# PIC32CX5112MTSH128S1 device description
Architecture: CORTEX-M4; Family: PIC32CXMT; Series: PIC32CXMTSH
Registers are 32-bit, read-write, no defined reset value unless marked. A register's access mark holds for its fields unless they carry their own. Offsets are from the block's base; [hi:lo] are bit positions; {n}, {i} and the like mark numbered series; 'fields as' and 'values as' point back to an identical list; <NAME> marks a mode.

## FLEXCOM (part 1 of 2) — Flexible Serial Communication
Instances: FLEXCOM{n} {0x40000000+0x4000*n} (n=0..7)
0x00 FLEX_MR — FLEXCOM Mode Register
  [1:0] OPMODE — FLEXCOM Operating Mode
    0=NO_COM (No communication); 1=USART (All UART related protocols are selected (RS232, RS485, IrDA, ISO7816, LIN,) SPI/TWI related registers are not accessible and have no impact on IOs.); 2=SPI (SPI operating mode is selected. USART/TWI related registers are not accessible and have no impact on IOs.); 3=TWI (All TWI related protocols are selected (TWI, SMBus). USART/SPI related registers are not accessible and have no impact on IOs.)
0x10 FLEX_RHR ro — FLEXCOM Receive Holding Register
  [15:0] RXDATA — Receive Data
0x20 FLEX_THR — FLEXCOM Transmit Holding Register
  [15:0] TXDATA — Transmit Data
0x100 FLEX_RPR — Receive Pointer Register
  [31:0] RXPTR
0x104 FLEX_RCR — Receive Counter Register
  [15:0] RXCTR
0x108 FLEX_TPR — Transmit Pointer Register
  [31:0] TXPTR — Transmit Counter Register
0x10C FLEX_TCR — Transmit Counter Register
  [15:0] TXCTR
0x110 FLEX_RNPR — Receive Next Pointer Register
  [31:0] RXNPTR — Receive Next Pointer
0x114 FLEX_RNCR — Receive Next Counter Register
  [15:0] RXNCTR — Receive Next Counter
0x118 FLEX_TNPR — Transmit Next Pointer Register
  [31:0] TXNPTR — Transmit Next Pointer
0x11C FLEX_TNCR — Transmit Next Counter Register
  [15:0] TXNCTR — Transmit Counter Next
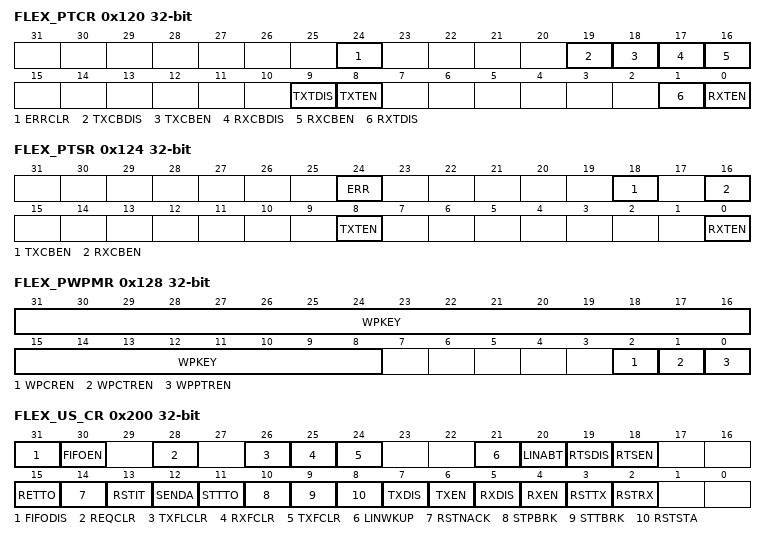
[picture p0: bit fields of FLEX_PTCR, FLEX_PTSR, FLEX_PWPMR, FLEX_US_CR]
0x120 FLEX_PTCR wo — Transfer Control Register
  [24] ERRCLR — Transfer Bus Error Clear
  [19] TXCBDIS — Transmitter Circular Buffer Disable
  [18] TXCBEN — Transmitter Circular Buffer Enable
  [17] RXCBDIS — Receiver Circular Buffer Disable
  [16] RXCBEN — Receiver Circular Buffer Enable
  [9] TXTDIS — Transmitter Transfer Disable
  [8] TXTEN — Transmitter Transfer Enable
  [1] RXTDIS — Receiver Transfer Disable
  [0] RXTEN — Receiver Transfer Enable
0x124 FLEX_PTSR ro — Transfer Status Register
  [24] ERR — Transfer Bus Error
  [18] TXCBEN — Transmitter Circular Buffer Enable
  [16] RXCBEN — Receiver Circular Buffer Enable
  [8] TXTEN — Transmitter Transfer Enable
  [0] RXTEN — Receiver Transfer Enable
0x128 FLEX_PWPMR — Write Protection Mode Register
  [31:8] WPKEY — Write Protection Key
    0x504443=PASSWD (Writing any other value in this field aborts the write operation. Always reads as 0.)
  [2] WPCREN — Write Protection Control Register Enable
  [1] WPCTREN — Write Protection Counter Registers Enable
  [0] WPPTREN — Write Protection Pointer Registers Enable
0x200 FLEX_US_CR wo — USART Control Register
  [31] FIFODIS — FIFO Disable
  [30] FIFOEN — FIFO Enable
  [28] REQCLR — Request to Clear the Comparison Trigger
  [26] TXFLCLR — Transmit FIFO Lock CLEAR
  [25] RXFCLR — Receive FIFO Clear
  [24] TXFCLR — Transmit FIFO Clear
  [21] LINWKUP — Send LIN Wakeup Signal
  [20] LINABT — Abort LIN Transmission
  [19] RTSDIS — Request to Send Disable
  [18] RTSEN — Request to Send Enable
  [15] RETTO — Start Timeout Immediately
  [14] RSTNACK — Reset Non Acknowledge
  [13] RSTIT — Reset Iterations
  [12] SENDA — Send Address
  [11] STTTO — Clear TIMEOUT Flag and Start Timeout After Next Character Received
  [10] STPBRK — Stop Break
  [9] STTBRK — Start Break
  [8] RSTSTA — Reset Status Bits
  [7] TXDIS — Transmitter Disable
  [6] TXEN — Transmitter Enable
  [5] RXDIS — Receiver Disable
  [4] RXEN — Receiver Enable
  [3] RSTTX — Reset Transmitter
  [2] RSTRX — Reset Receiver
0x204 FLEX_US_MR — USART Mode Register
  [31] ONEBIT <DEFAULT> — Start Frame Delimiter Selector
  [30] MODSYNC <DEFAULT> — Manchester Synchronization Mode
  [29] MAN <DEFAULT> — Manchester Encoder/Decoder Enable
  [28] FILTER <DEFAULT> — Receive Line Filter
  [26:24] MAX_ITERATION <DEFAULT> — Maximum Number of Automatic Iteration
  [23] INVDATA <DEFAULT> — Inverted Data
  [22] VAR_SYNC <DEFAULT> — Variable Synchronization of Command/Data Sync Start Frame Delimiter
  [21] DSNACK <DEFAULT> — Disable Successive NACK
  [20] INACK <DEFAULT> — Inhibit Non Acknowledge
  [19] OVER <DEFAULT> — Oversampling Mode
  [18] CLKO <DEFAULT> — Clock Output Select
  [17] MODE9 <DEFAULT> — 9-bit Character Length
  [16] MSBF <DEFAULT> — Bit Order
  [15:14] CHMODE <DEFAULT> — Channel Mode
    0=NORMAL (Normal mode); 1=AUTOMATIC (Automatic Echo. Receiver input is connected to the TXD pin.); 2=LOCAL_LOOPBACK (Local Loopback. Transmitter output is connected to the Receiver Input.); 3=REMOTE_LOOPBACK (Remote Loopback. RXD pin is internally connected to the TXD pin.)
  [13:12] NBSTOP <DEFAULT> — Number of Stop Bits
    0=1_BIT (1 stop bit); 1=1_5_BIT (1.5 stop bit (SYNC = 0) or reserved (SYNC = 1)); 2=2_BIT (2 stop bits)
  [11:9] PAR <DEFAULT> — Parity Type
    0=EVEN (Even parity); 1=ODD (Odd parity); 2=SPACE (Parity forced to 0 (Space)); 3=MARK (Parity forced to 1 (Mark)); 4=NO (No parity); 6=MULTIDROP (Multidrop mode)
  [8] SYNC <DEFAULT> — Synchronous Mode Select
  [7:6] CHRL <DEFAULT> — Character Length
    {v}={v+5}_BIT (Character length is {v+5} bits) (v=0..3)
  [5:4] USCLKS <DEFAULT> — Clock Selection
    0=MCK (Peripheral clock is selected); 1=DIV (Peripheral clock divided (DIV = 8) is selected); 2=GCLK (PMC generic clock is selected. If the SCK pin is driven (CLKO = 1), the CD field must be greater than 1.); 3=SCK (External pin SCK is selected)
  [3:0] USART_MODE <DEFAULT> — USART Mode of Operation
    0=NORMAL (Normal mode); 1=RS485; 2=HW_HANDSHAKING (Hardware handshaking); 4=IS07816_T_0 (IS07816 Protocol: T = 0); 6=IS07816_T_1 (IS07816 Protocol: T = 1); 8=IRDA; 10=LIN_MASTER (LIN Host mode); 11=LIN_SLAVE (LIN Client mode); 12=DATA16BIT_MASTER (16-bit data host); 13=DATA16BIT_SLAVE (16-bit data client)
  [28] FILTER <OOK> — Receive Line Filter
  [21] OOKEN <OOK> — OOK Modulation/Demodulation Enabled
  [20] OOKRXD <OOK> — OOK Demodulation Input Selection
  [19] OVER <OOK> — Oversampling Mode
  [18] CLKO <OOK> — Clock Output Select
  [17] MODE9 <OOK> — 9-bit Character Length
  [16] MSBF <OOK> — Bit Order
  [15:14] CHMODE <OOK> — Channel Mode
    values as CHMODE<DEFAULT>
  [13:12] NBSTOP <OOK> — Number of Stop Bits
    0=_1_BIT (1 stop bit); 1=_1_5_BIT (1.5 stop bit (SYNC = 0) or reserved (SYNC = 1)); 2=_2_BIT (2 stop bits)
  [11:9] PAR <OOK> — Parity Type
    values as PAR<DEFAULT>
  [8] SYNC <OOK> — Synchronous Mode Select
  [7:6] CHRL <OOK> — Character Length
    {v}=_{v+5}_BIT (Character length is {v+5} bits.) (v=0..3)
  [5:4] USCLKS <OOK> — Clock Selection
    0=MCK (Peripheral clock is selected.); 1=DIV (Peripheral clock divided (DIV=8) is selected.); 2=PCK (PMC programmable clock (PCK) is selected. If the SCK pin is driven (CLKO = 1), the CD field must be greater than 1.); 3=SCK (Serial clock (SCK) is selected.)
  [3:0] USART_MODE <OOK> — USART Mode of Operation
    0=NORMAL (Normal mode)
0x208 FLEX_US_IER wo — USART Interrupt Enable Register
  [24] MANE <DEFAULT> — Manchester Error Interrupt Enable
  [22] CMP <DEFAULT> — Comparison Interrupt Enable
  [19] CTSIC <DEFAULT> — Clear to Send Input Change Interrupt Enable
  [13] NACK <DEFAULT> — Non Acknowledge Interrupt Enable
  [12] RXBUFF <DEFAULT> — Buffer Full Interrupt Enable (available in all USART modes of operation)
  [11] TXBUFE <DEFAULT> — Buffer Empty Interrupt Enable (available in all USART modes of operation)
  [10] ITER <DEFAULT> — Max number of Repetitions Reached Interrupt Enable
  [9] TXEMPTY <DEFAULT> — TXEMPTY Interrupt Enable
  [8] TIMEOUT <DEFAULT> — Timeout Interrupt Enable
  [7] PARE <DEFAULT> — Parity Error Interrupt Enable
  [6] FRAME <DEFAULT> — Framing Error Interrupt Enable
  [5] OVRE <DEFAULT> — Overrun Error Interrupt Enable
  [4] ENDTX <DEFAULT> — End of Transmit Interrupt Enable (available in all USART modes of operation)
  [3] ENDRX <DEFAULT> — End of Receive Transfer Interrupt Enable (available in all USART modes of operation)
  [2] RXBRK <DEFAULT> — Receiver Break Interrupt Enable
  [1] TXRDY <DEFAULT> — TXRDY Interrupt Enable
  [0] RXRDY <DEFAULT> — RXRDY Interrupt Enable
  [31] LINHTE <LIN_MODE> — LIN Header Timeout Error Interrupt Enable
  [30] LINSTE <LIN_MODE> — LIN Synch Tolerance Error Interrupt Enable
  [29] LINSNRE <LIN_MODE> — LIN Client Not Responding Error Interrupt Enable
  [28] LINCE <LIN_MODE> — LIN Checksum Error Interrupt Enable
  [27] LINIPE <LIN_MODE> — LIN Identifier Parity Interrupt Enable
  [26] LINISFE <LIN_MODE> — LIN Inconsistent Synch Field Error Interrupt Enable
  [25] LINBE <LIN_MODE> — LIN Bus Error Interrupt Enable
  [15] LINTC <LIN_MODE> — LIN Transfer Completed Interrupt Enable
  [14] LINID <LIN_MODE> — LIN Identifier Sent or LIN Identifier Received Interrupt Enable
  [13] LINBK <LIN_MODE> — LIN Break Sent or LIN Break Received Interrupt Enable
  [12] RXBUFF <LIN_MODE> — Buffer Full Interrupt Enable
  [11] TXBUFE <LIN_MODE> — Buffer Empty Interrupt Enable
  [9] TXEMPTY <LIN_MODE> — TXEMPTY Interrupt Enable
  [8] TIMEOUT <LIN_MODE> — Timeout Interrupt Enable
  [7] PARE <LIN_MODE> — Parity Error Interrupt Enable
  [6] FRAME <LIN_MODE> — Framing Error Interrupt Enable
  [5] OVRE <LIN_MODE> — Overrun Error Interrupt Enable
  [4] ENDTX <LIN_MODE> — End of Transmit Interrupt Enable
  [3] ENDRX <LIN_MODE> — End of Receive Transfer Interrupt Enable
  [1] TXRDY <LIN_MODE> — TXRDY Interrupt Enable
  [0] RXRDY <LIN_MODE> — RXRDY Interrupt Enable
0x20C FLEX_US_IDR wo — USART Interrupt Disable Register
  [24] MANE <DEFAULT> — Manchester Error Interrupt Disable
  [22] CMP <DEFAULT> — Comparison Interrupt Disable
  [19] CTSIC <DEFAULT> — Clear to Send Input Change Interrupt Disable
  [13] NACK <DEFAULT> — Non Acknowledge Interrupt Disable
  [12] RXBUFF <DEFAULT> — Buffer Full Interrupt Disable (available in all USART modes of operation)
  [11] TXBUFE <DEFAULT> — Buffer Empty Interrupt Disable (available in all USART modes of operation)
  [10] ITER <DEFAULT> — Max Number of Repetitions Reached Interrupt Disable
  [9] TXEMPTY <DEFAULT> — TXEMPTY Interrupt Disable
  [8] TIMEOUT <DEFAULT> — Timeout Interrupt Disable
  [7] PARE <DEFAULT> — Parity Error Interrupt Disable
  [6] FRAME <DEFAULT> — Framing Error Interrupt Disable
  [5] OVRE <DEFAULT> — Overrun Error Interrupt Disable
  [4] ENDTX <DEFAULT> — End of Transmit Interrupt Disable (available in all USART modes of operation)
  [3] ENDRX <DEFAULT> — End of Receive Transfer Interrupt Disable (available in all USART modes of operation)
  [2] RXBRK <DEFAULT> — Receiver Break Interrupt Disable
  [1] TXRDY <DEFAULT> — TXRDY Interrupt Disable
  [0] RXRDY <DEFAULT> — RXRDY Interrupt Disable
  [31] LINHTE <LIN_MODE> — LIN Header Timeout Error Interrupt Disable
  [30] LINSTE <LIN_MODE> — LIN Synch Tolerance Error Interrupt Disable
  [29] LINSNRE <LIN_MODE> — LIN Client Not Responding Error Interrupt Disable
  [28] LINCE <LIN_MODE> — LIN Checksum Error Interrupt Disable
  [27] LINIPE <LIN_MODE> — LIN Identifier Parity Interrupt Disable
  [26] LINISFE <LIN_MODE> — LIN Inconsistent Synch Field Error Interrupt Disable
  [25] LINBE <LIN_MODE> — LIN Bus Error Interrupt Disable
  [15] LINTC <LIN_MODE> — LIN Transfer Completed Interrupt Disable
  [14] LINID <LIN_MODE> — LIN Identifier Sent or LIN Identifier Received Interrupt Disable
  [13] LINBK <LIN_MODE> — LIN Break Sent or LIN Break Received Interrupt Disable
  [12] RXBUFF <LIN_MODE> — Buffer Full Interrupt Disable
  [11] TXBUFE <LIN_MODE> — Buffer Empty Interrupt Disable
  [9] TXEMPTY <LIN_MODE> — TXEMPTY Interrupt Disable
  [8] TIMEOUT <LIN_MODE> — Timeout Interrupt Disable
  [7] PARE <LIN_MODE> — Parity Error Interrupt Disable
  [6] FRAME <LIN_MODE> — Framing Error Interrupt Disable
  [5] OVRE <LIN_MODE> — Overrun Error Interrupt Disable
  [4] ENDTX <LIN_MODE> — End of Transmit Interrupt Disable
  [3] ENDRX <LIN_MODE> — End of Receive Transfer Interrupt Disable
  [1] TXRDY <LIN_MODE> — TXRDY Interrupt Disable
  [0] RXRDY <LIN_MODE> — RXRDY Interrupt Disable
0x210 FLEX_US_IMR ro — USART Interrupt Mask Register
  [24] MANE <DEFAULT> — Manchester Error Interrupt Mask
  [22] CMP <DEFAULT> — Comparison Interrupt Mask
  [19] CTSIC <DEFAULT> — Clear to Send Input Change Interrupt Mask
  [13] NACK <DEFAULT> — Non Acknowledge Interrupt Mask
  [12] RXBUFF <DEFAULT> — Buffer Full Interrupt Mask (available in all USART modes of operation)
  [11] TXBUFE <DEFAULT> — Buffer Empty Interrupt Mask (available in all USART modes of operation)
  [10] ITER <DEFAULT> — Max Number of Repetitions Reached Interrupt Mask
  [9] TXEMPTY <DEFAULT> — TXEMPTY Interrupt Mask
  [8] TIMEOUT <DEFAULT> — Timeout Interrupt Mask
  [7] PARE <DEFAULT> — Parity Error Interrupt Mask
  [6] FRAME <DEFAULT> — Framing Error Interrupt Mask
  [5] OVRE <DEFAULT> — Overrun Error Interrupt Mask
  [4] ENDTX <DEFAULT> — End of Transmit Interrupt Mask (available in all USART modes of operation)
  [3] ENDRX <DEFAULT> — End of Receive Transfer Interrupt Mask (available in all USART modes of operation)
  [2] RXBRK <DEFAULT> — Receiver Break Interrupt Mask
  [1] TXRDY <DEFAULT> — TXRDY Interrupt Mask
  [0] RXRDY <DEFAULT> — RXRDY Interrupt Mask
  [31] LINHTE <LIN_MODE> — LIN Header Timeout Error Interrupt Mask
  [30] LINSTE <LIN_MODE> — LIN Synch Tolerance Error Interrupt Mask
  [29] LINSNRE <LIN_MODE> — LIN Client Not Responding Error Interrupt Mask
  [28] LINCE <LIN_MODE> — LIN Checksum Error Interrupt Mask
  [27] LINIPE <LIN_MODE> — LIN Identifier Parity Interrupt Mask
  [26] LINISFE <LIN_MODE> — LIN Inconsistent Synch Field Error Interrupt Mask
  [25] LINBE <LIN_MODE> — LIN Bus Error Interrupt Mask
  [15] LINTC <LIN_MODE> — LIN Transfer Completed Interrupt Mask
  [14] LINID <LIN_MODE> — LIN Identifier Sent or LIN Identifier Received Interrupt Mask
  [13] LINBK <LIN_MODE> — LIN Break Sent or LIN Break Received Interrupt Mask
  [12] RXBUFF <LIN_MODE> — Buffer Full Interrupt Mask
  [11] TXBUFE <LIN_MODE> — Buffer Empty Interrupt Mask
  [9] TXEMPTY <LIN_MODE> — TXEMPTY Interrupt Mask
  [8] TIMEOUT <LIN_MODE> — Timeout Interrupt Mask
  [7] PARE <LIN_MODE> — Parity Error Interrupt Mask
  [6] FRAME <LIN_MODE> — Framing Error Interrupt Mask
  [5] OVRE <LIN_MODE> — Overrun Error Interrupt Mask
  [4] ENDTX <LIN_MODE> — End of Transmit Interrupt Mask
  [3] ENDRX <LIN_MODE> — End of Receive Transfer Interrupt Mask
  [1] TXRDY <LIN_MODE> — TXRDY Interrupt Mask
  [0] RXRDY <LIN_MODE> — RXRDY Interrupt Mask
0x214 FLEX_US_CSR ro — USART Channel Status Register
  [24] MANE <DEFAULT> — Manchester Error
  [23] CTS <DEFAULT> — Image of CTS Input
  [22] CMP <DEFAULT> — Comparison Status
  [19] CTSIC <DEFAULT> — Clear to Send Input Change Flag
  [13] NACK <DEFAULT> — Non Acknowledge Interrupt
  [12] RXBUFF <DEFAULT> — RX Buffer Full (cleared by writing FLEX_US_RCR or FLEX_US_RNCR)
  [11] TXBUFE <DEFAULT> — TX Buffer Empty (cleared by writing FLEX_US_TCR or FLEX_US_TNCR)
  [10] ITER <DEFAULT> — Max Number of Repetitions Reached
  [9] TXEMPTY <DEFAULT> — Transmitter Empty (cleared by writing FLEX_US_THR)
  [8] TIMEOUT <DEFAULT> — Receiver Timeout
  [7] PARE <DEFAULT> — Parity Error
  [6] FRAME <DEFAULT> — Framing Error
  [5] OVRE <DEFAULT> — Overrun Error
  [4] ENDTX <DEFAULT> — End of TX Buffer (cleared by writing FLEX_US_TCR or FLEX_US_TNCR)
  [3] ENDRX <DEFAULT> — End of RX Buffer (cleared by writing FLEX_US_RCR or FLEX_US_RNCR)
  [2] RXBRK <DEFAULT> — Break Received/End of Break
  [1] TXRDY <DEFAULT> — Transmitter Ready (cleared by writing FLEX_US_THR)
  [0] RXRDY <DEFAULT> — Receiver Ready (cleared by reading FLEX_US_RHR)
  [31] LINHTE <LIN_MODE> — LIN Header Timeout Error
  [30] LINSTE <LIN_MODE> — LIN Synch Tolerance Error
  [29] LINSNRE <LIN_MODE> — LIN Client Not Responding Error
  [28] LINCE <LIN_MODE> — LIN Checksum Error
  [27] LINIPE <LIN_MODE> — LIN Identifier Parity Error
  [26] LINISFE <LIN_MODE> — LIN Inconsistent Synch Field Error
  [25] LINBE <LIN_MODE> — LIN Bit Error
  [23] LINBLS <LIN_MODE> — LIN Bus Line Status
  [15] LINTC <LIN_MODE> — LIN Transfer Completed
  [14] LINID <LIN_MODE> — LIN Identifier Sent or LIN Identifier Received
  [13] LINBK <LIN_MODE> — LIN Break Sent or LIN Break Received
  [12] RXBUFF <LIN_MODE> — RX Buffer Full (cleared by writing FLEX_US_RCR or FLEX_US_RNCR)
  [11] TXBUFE <LIN_MODE> — TX Buffer Empty (cleared by writing FLEX_US_TCR or FLEX_US_TNCR)
  [9] TXEMPTY <LIN_MODE> — Transmitter Empty (cleared by writing FLEX_US_THR)
  [8] TIMEOUT <LIN_MODE> — Receiver Timeout
  [7] PARE <LIN_MODE> — Parity Error
  [6] FRAME <LIN_MODE> — Framing Error
  [5] OVRE <LIN_MODE> — Overrun Error
  [4] ENDTX <LIN_MODE> — End of TX Buffer (cleared by writing FLEX_US_TCR or FLEX_US_TNCR)
  [3] ENDRX <LIN_MODE> — End of RX Buffer (cleared by writing FLEX_US_RCR or FLEX_US_RNCR)
  [1] TXRDY <LIN_MODE> — Transmitter Ready (cleared by writing FLEX_US_THR)
  [0] RXRDY <LIN_MODE> — Receiver Ready (cleared by reading FLEX_US_RHR)
0x218 FLEX_US_RHR ro — USART Receive Holding Register
  [15] RXSYNH <DEFAULT> — Received Sync
  [8:0] RXCHR <DEFAULT> — Received Character
  [8n+7:8n] RXCHR{n} <FIFO_MULTI_DATA> (n=0..3) — Received Characters
0x21C FLEX_US_THR wo — USART Transmit Holding Register
  [15] TXSYNH <DEFAULT> — Sync Field to be Transmitted
  [8:0] TXCHR <DEFAULT> — Character to be Transmitted
  [8n+7:8n] TXCHR{n} <FIFO_MULTI_DATA> (n=0..3) — Character to be Transmitted
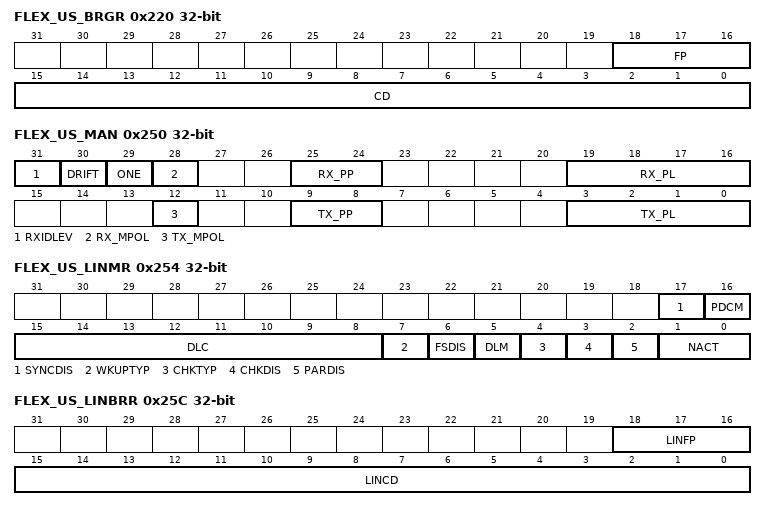
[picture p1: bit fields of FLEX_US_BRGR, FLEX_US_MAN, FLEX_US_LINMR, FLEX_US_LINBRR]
0x220 FLEX_US_BRGR — USART Baud Rate Generator Register
  [18:16] FP — Fractional Part
  [15:0] CD — Clock Divider
0x224 FLEX_US_RTOR — USART Receiver Timeout Register
  [16:0] TO — Timeout Value
0x228 FLEX_US_TTGR — USART Transmitter Timeguard Register
  [7:0] TG — Timeguard Value
0x240 FLEX_US_FIDI — USART FI DI Ratio Register
  [15:0] FI_DI_RATIO — FI Over DI Ratio Value
0x244 FLEX_US_NER ro — USART Number of Errors Register
  [7:0] NB_ERRORS — Number of Errors
0x24C FLEX_US_IF — USART IrDA Filter Register
  [7:0] IRDA_FILTER
0x250 FLEX_US_MAN — USART Manchester Configuration Register
  [31] RXIDLEV — Receiver Idle Value
  [30] DRIFT — Drift Compensation
  [29] ONE — Must Be Set to 1
  [28] RX_MPOL — Receiver Manchester Polarity
  [25:24] RX_PP — Receiver Preamble Pattern detected
    0=ALL_ONE (The preamble is composed of '1's); 1=ALL_ZERO (The preamble is composed of '0's); 2=ZERO_ONE (The preamble is composed of '01's); 3=ONE_ZERO (The preamble is composed of '10's)
  [19:16] RX_PL — Receiver Preamble Length
  [12] TX_MPOL — Transmitter Manchester Polarity
  [9:8] TX_PP — Transmitter Preamble Pattern
    values as RX_PP
  [3:0] TX_PL — Transmitter Preamble Length
0x254 FLEX_US_LINMR — USART LIN Mode Register
  [17] SYNCDIS — Synchronization Disable
  [16] PDCM — PDC Mode
  [15:8] DLC — Data Length Control
  [7] WKUPTYP — Wakeup Signal Type
  [6] FSDIS — Frame Slot Mode Disable
  [5] DLM — Data Length Mode
  [4] CHKTYP — Checksum Type
  [3] CHKDIS — Checksum Disable
  [2] PARDIS — Parity Disable
  [1:0] NACT — LIN Node Action
    0=PUBLISH (The USART transmits the response.); 1=SUBSCRIBE (The USART receives the response.); 2=IGNORE (The USART does not transmit and does not receive the response.)
0x258 FLEX_US_LINIR — USART LIN Identifier Register
  [7:0] IDCHR — Identifier Character
0x25C FLEX_US_LINBRR ro — USART LIN Baud Rate Register
  [18:16] LINFP — Fractional Part after Synchronization
  [15:0] LINCD — Clock Divider after Synchronization
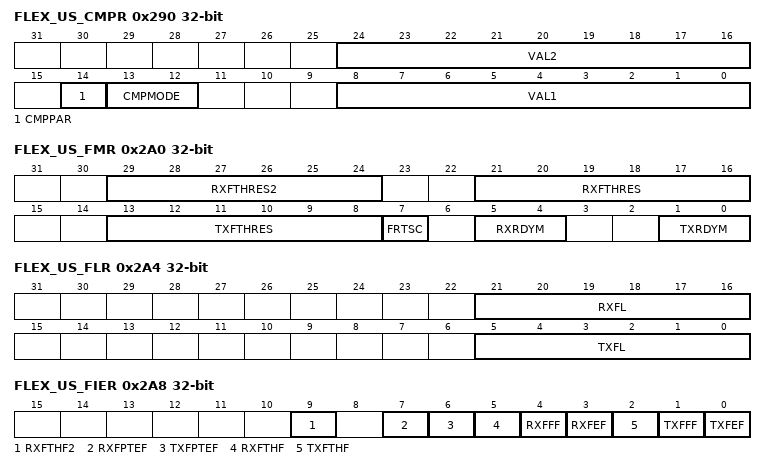
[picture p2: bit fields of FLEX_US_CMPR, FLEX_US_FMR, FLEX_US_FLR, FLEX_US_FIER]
0x290 FLEX_US_CMPR — USART Comparison Register
  [24:16] VAL2 — Second Comparison Value for Received Character
  [14] CMPPAR — Compare Parity
  [13:12] CMPMODE — Comparison Mode
    0=FLAG_ONLY (Any character is received and comparison function drives CMP flag.); 1=START_CONDITION (Comparison condition must be met to start reception.); 2=FILTER (Comparison must be met to receive the current data only)
  [8:0] VAL1 — First Comparison Value for Received Character
0x2A0 FLEX_US_FMR — USART FIFO Mode Register
  [29:24] RXFTHRES2 — Receive FIFO Threshold 2
  [21:16] RXFTHRES — Receive FIFO Threshold
  [13:8] TXFTHRES — Transmit FIFO Threshold
  [7] FRTSC — FIFO RTS Pin Control enable (Hardware Handshaking mode only)
  [5:4] RXRDYM — Receiver Ready Mode
    0=ONE_DATA (RXRDY will be at level '1' when at least one unread data is in the receive FIFO. When DMA is enabled to transfer data and FLEX_US_MR.MODE9=0 (up to 8 bits to transfer on the line), the chunk of 1 byte must be configured in the DMA. If the transfer is performed by software, the access type must be defined as a byte.); 1=TWO_DATA (RXRDY will be at level '1' when at least two unread data are in the receive FIFO. To minimize system bus load, when DMA is enabled to transfer data and FLEX_US_MR.MODE9=0 (up to 8 bits to transfer on the line), the chunk of 1 halfword (1 halfword carries 2 bytes) must be configured in the DMA (chunk size=1 and halfword access). If the transfer is performed by software, the access type can be defined as byte (1 byte per access, 2 accesses) or halfword (2 bytes per access, 1 single access).); 2=FOUR_DATA (RXRDY will be at level '1' when at least four unread data are in the receive FIFO. To minimize system bus load, when DMA is enabled to transfer data and FLEX_US_MR.MODE9=0 (up to 8 bits to transfer on the line), the chunk of 1 word (1 word carries 4 bytes) must be configured in the DMA. If the transfer is performed by software, the access type can be defined as byte (1 byte per access, 4 accesses), halfword (2 bytes per access, 2 accesses) or word (4 bytes per access, 1 single access).)
  [1:0] TXRDYM — Transmitter Ready Mode
    0=ONE_DATA (TXRDY will be at level '1' when at least one data can be written in the transmit FIFO. When DMA is enabled to transfer data and FLEX_US_MR.MODE9=0 (up to 8 bits to transfer on the line), the chunk of 1 byte must be configured in the DMA. If the transfer is performed by software, the access type must be defined as a byte.); 1=TWO_DATA (TXRDY will be at level '1' when at least two data can be written in the transmit FIFO. To minimize system bus load, when DMA is enabled to transfer data and FLEX_US_MR.MODE9=0 (up to 8 bits to transfer on the line), the chunk of 1 halfword (1 halfword carries 2 bytes) must be configured in the DMA. If the transfer is performed by software, the access type can be defined as byte (1 byte per access, 2 accesses) or halfword (2 bytes per access, 1 single access).); 2=FOUR_DATA (TXRDY will be at level '1' when at least four data can be written in the transmit FIFO. To minimize system bus load, when DMA is enabled to transfer data and FLEX_US_MR.MODE9=0 (up to 8 bits to transfer on the line), the chunk of 1 word (1 word carries 4 bytes) must be configured in the DMA (chunk size=1 and word access). If the transfer is performed by software, the access type can be defined as byte (1 byte per access, 4 accesses), halfword (2 bytes per access, 2 accesses) or word (4 bytes per access, 1 single access).)
0x2A4 FLEX_US_FLR ro — USART FIFO Level Register
  [21:16] RXFL — Receive FIFO Level
  [5:0] TXFL — Transmit FIFO Level
0x2A8 FLEX_US_FIER wo — USART FIFO Interrupt Enable Register
  [9] RXFTHF2 — RXFTHF2 Interrupt Enable
  [7] RXFPTEF — RXFPTEF Interrupt Enable
  [6] TXFPTEF — TXFPTEF Interrupt Enable
  [5] RXFTHF — RXFTHF Interrupt Enable
  [4] RXFFF — RXFFF Interrupt Enable
  [3] RXFEF — RXFEF Interrupt Enable
  [2] TXFTHF — TXFTHF Interrupt Enable
  [1] TXFFF — TXFFF Interrupt Enable
  [0] TXFEF — TXFEF Interrupt Enable
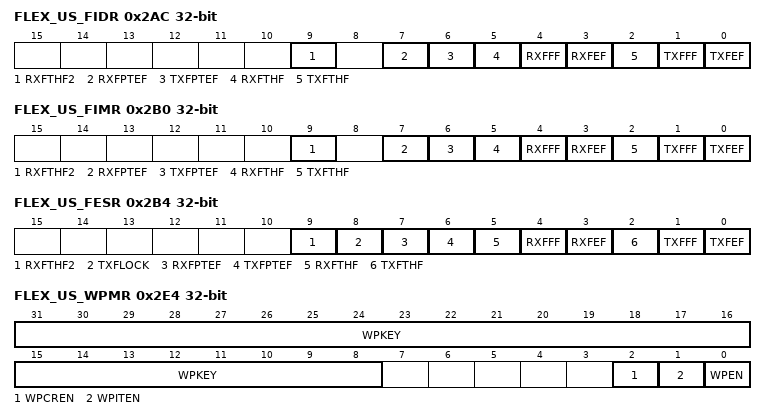
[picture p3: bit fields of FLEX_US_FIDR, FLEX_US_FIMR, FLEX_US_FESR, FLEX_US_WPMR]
0x2AC FLEX_US_FIDR wo — USART FIFO Interrupt Disable Register
  [9] RXFTHF2 — RXFTHF2 Interrupt Disable
  [7] RXFPTEF — RXFPTEF Interrupt Disable
  [6] TXFPTEF — TXFPTEF Interrupt Disable
  [5] RXFTHF — RXFTHF Interrupt Disable
  [4] RXFFF — RXFFF Interrupt Disable
  [3] RXFEF — RXFEF Interrupt Disable
  [2] TXFTHF — TXFTHF Interrupt Disable
  [1] TXFFF — TXFFF Interrupt Disable
  [0] TXFEF — TXFEF Interrupt Disable
0x2B0 FLEX_US_FIMR ro — USART FIFO Interrupt Mask Register
  [9] RXFTHF2 — RXFTHF2 Interrupt Mask
  [7] RXFPTEF — RXFPTEF Interrupt Mask
  [6] TXFPTEF — TXFPTEF Interrupt Mask
  [5] RXFTHF — RXFTHF Interrupt Mask
  [4] RXFFF — RXFFF Interrupt Mask
  [3] RXFEF — RXFEF Interrupt Mask
  [2] TXFTHF — TXFTHF Interrupt Mask
  [1] TXFFF — TXFFF Interrupt Mask
  [0] TXFEF — TXFEF Interrupt Mask
0x2B4 FLEX_US_FESR ro — USART FIFO Event Status Register
  [9] RXFTHF2 — Receive FIFO Threshold Flag 2 (cleared by writing the FLEX_US_CR.RSTSTA bit)
  [8] TXFLOCK — Transmit FIFO Lock
  [7] RXFPTEF — Receive FIFO Pointer Error Flag
  [6] TXFPTEF — Transmit FIFO Pointer Error Flag
  [5] RXFTHF — Receive FIFO Threshold Flag (cleared by writing the FLEX_US_CR.RSTSTA bit)
  [4] RXFFF — Receive FIFO Full Flag (cleared by writing the FLEX_US_CR.RSTSTA bit)
  [3] RXFEF — Receive FIFO Empty Flag (cleared by writing the FLEX_US_CR.RSTSTA bit)
  [2] TXFTHF — Transmit FIFO Threshold Flag (cleared by writing the FLEX_US_CR.RSTSTA bit)
  [1] TXFFF — Transmit FIFO Full Flag (cleared by writing the FLEX_US_CR.RSTSTA bit)
  [0] TXFEF — Transmit FIFO Empty Flag (cleared by writing the FLEX_US_CR.RSTSTA bit)
0x2E4 FLEX_US_WPMR — USART Write Protection Mode Register
  [31:8] WPKEY — Write Protection Key
    0x555341=PASSWD (Writing any other value in this field aborts the write operation of bits WPEN, WPITEN and WPCREN. Always reads as 0.)
  [2] WPCREN — Write Protection Control Enable
  [1] WPITEN — Write Protection Interrupt Enable
  [0] WPEN — Write Protection Enable
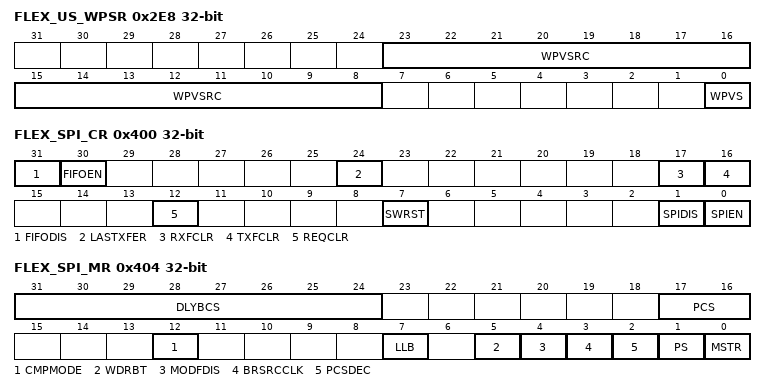
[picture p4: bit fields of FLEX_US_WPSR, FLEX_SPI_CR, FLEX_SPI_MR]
0x2E8 FLEX_US_WPSR ro — USART Write Protection Status Register
  [23:8] WPVSRC — Write Protection Violation Source
  [0] WPVS — Write Protection Violation Status
0x400 FLEX_SPI_CR wo — SPI Control Register
  [31] FIFODIS — FIFO Disable
  [30] FIFOEN — FIFO Enable
  [24] LASTXFER — Last Transfer
  [17] RXFCLR — Receive FIFO Clear
  [16] TXFCLR — Transmit FIFO Clear
  [12] REQCLR — Request to Clear the Comparison Trigger
  [7] SWRST — SPI Software Reset
  [1] SPIDIS — SPI Disable
  [0] SPIEN — SPI Enable
0x404 FLEX_SPI_MR — SPI Mode Register
  [31:24] DLYBCS — Delay Between Chip Selects
  [17:16] PCS — Peripheral Chip Select
  [12] CMPMODE — Comparison Mode
    0=FLAG_ONLY (Any character is received and comparison function drives CMP flag.); 1=START_CONDITION (Comparison condition must be met to start reception of all incoming characters until REQCLR is set.)
  [7] LLB — Local Loopback Enable
  [5] WDRBT — Wait Data Read Before Transfer
  [4] MODFDIS — Mode Fault Detection
  [3] BRSRCCLK — Bit Rate Source Clock
    0=PERIPH_CLK (The peripheral clock is the source clock for the bit rate generation.); 1=GCLK (GCLK is the source clock for the bit rate generation, thus the bit rate can be independent of the core/peripheral clock.)
  [2] PCSDEC — Chip Select Decode
  [1] PS — Peripheral Select
  [0] MSTR — Host/Client Mode

## Notices in the file
Copyright %copyright_year% Microchip Technology Inc.
SPDX-License-Identifier: Apache-2.0
Licensed under the Apache License, Version 2.0 (the "License");
you may not use this file except in compliance with the License.
You may obtain a copy of the License at
http://www.apache.org/licenses/LICENSE-2.0
Unless required by applicable law or agreed to in writing, software
distributed under the License is distributed on an "AS IS" BASIS,
WITHOUT WARRANTIES OR CONDITIONS OF ANY KIND, either express or implied.
See the License for the specific language governing permissions and
limitations under the License.
